AUTOSAR XML (schema 00044)
package /E40_Platform_System_SystemPackage/Components
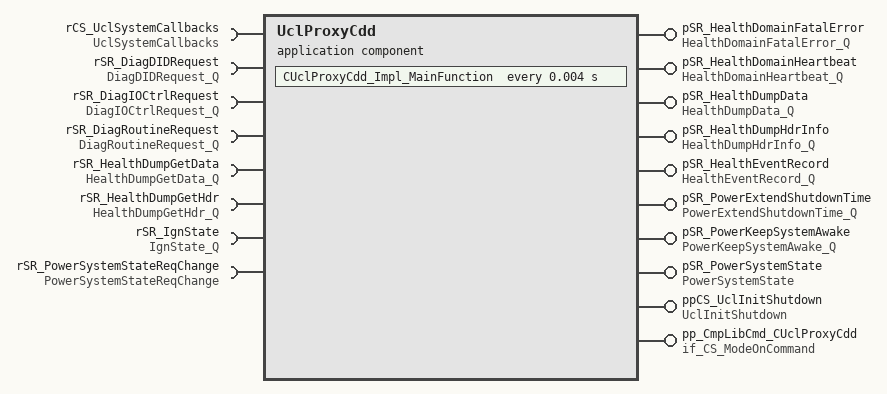
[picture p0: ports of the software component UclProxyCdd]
  application sw component type UclProxyCdd
    10 x provide port:
      pSR_HealthDomainFatalError: queued-sender-com-spec=HealthDomainFatalErrorData, provided-interface=HealthDomainFatalError_Q
      pSR_HealthDomainHeartbeat: queued-sender-com-spec=HealthDomainHeartbeatData, provided-interface=HealthDomainHeartbeat_Q
      pSR_HealthDumpData: queued-sender-com-spec=HealthDumpDataData, provided-interface=HealthDumpData_Q
      pSR_HealthDumpHdrInfo: queued-sender-com-spec=HealthDumpHdrInfoData, provided-interface=HealthDumpHdrInfo_Q
      pSR_HealthEventRecord: queued-sender-com-spec=HealthEventRecordData, provided-interface=HealthEventRecord_Q
      pSR_PowerExtendShutdownTime: queued-sender-com-spec=PowerExtendShutdownTimeData, provided-interface=PowerExtendShutdownTime_Q
      pSR_PowerKeepSystemAwake: queued-sender-com-spec=PowerKeepSystemAwakeData, provided-interface=PowerKeepSystemAwake_Q
      pSR_PowerSystemState: nonqueued-sender-com-spec{data-element=PowerSystemStateData, init-value=constant-reference=UclProxyCddPowerSystemStateDataValue0}, provided-interface=PowerSystemState
      ppCS_UclInitShutdown: provided-com-specs=[{operation=Impl_Initialize, queue-length=1}, {operation=Impl_Shutdown, queue-length=1}], provided-interface=UclInitShutdown
      pp_CmpLibCmd_CUclProxyCdd: server-com-spec{operation=Impl_OnCommand, queue-length=1}, provided-interface=if_CS_ModeOnCommand
    8 x require port:
      rCS_UclSystemCallbacks: required-com-specs=[ErrorNotification, LinkStatusChanged], required-interface=UclSystemCallbacks
      rSR_DiagDIDRequest: queued-receiver-com-spec{data-element=DiagDIDRequestData, queue-length=2}, required-interface=DiagDIDRequest_Q
      rSR_DiagIOCtrlRequest: queued-receiver-com-spec{data-element=DiagIOCtrlRequestData, queue-length=2}, required-interface=DiagIOCtrlRequest_Q
      rSR_DiagRoutineRequest: queued-receiver-com-spec{data-element=DiagRoutineRequestData, queue-length=2}, required-interface=DiagRoutineRequest_Q
      rSR_HealthDumpGetData: queued-receiver-com-spec{data-element=HealthDumpGetDataData, queue-length=1}, required-interface=HealthDumpGetData_Q
      rSR_HealthDumpGetHdr: queued-receiver-com-spec{data-element=HealthDumpGetHdrData, queue-length=1}, required-interface=HealthDumpGetHdr_Q
      rSR_IgnState: queued-receiver-com-spec{data-element=IgnStateData, queue-length=5}, required-interface=IgnState_Q
      rSR_PowerSystemStateReqChange: nonqueued-receiver-com-spec{data-element=PowerSystemStateReqChangeData, init-value=constant-reference=UclProxyCddPowerSystemStateReqChangeDataValue0}, required-interface=PowerSystemStateReqChange
    behavior IB_UclProxyCdd
      operation invoked event OIE_ppCS_UclInitShutdown_CUclProxyCdd_Impl_InitializeTrigByImpl_Initialize: start-on-event=CUclProxyCdd_Impl_Initialize, operation=ppCS_UclInitShutdown.Impl_Initialize
      timing event TECUclProxyCdd_Impl_MainFunction: start-on-event=CUclProxyCdd_Impl_MainFunction, period=0.004
      operation invoked event OIE_pp_CmpLibCmd_CUclProxyCdd_CUclProxyCdd_Impl_OnCommandTrigByImpl_OnCommand: start-on-event=CUclProxyCdd_Impl_OnCommand, operation=pp_CmpLibCmd_CUclProxyCdd.Impl_OnCommand
      operation invoked event OIE_ppCS_UclInitShutdown_CUclProxyCdd_Impl_ShutdownTrigByImpl_Shutdown: start-on-event=CUclProxyCdd_Impl_Shutdown, operation=ppCS_UclInitShutdown.Impl_Shutdown
      data received event DREOnDre_HealthDumpGetDataTrigByHealthDumpGetDataData: start-on-event=OnDre_HealthDumpGetData, data=rSR_HealthDumpGetData.HealthDumpGetDataData
      data received event DREOnDre_HealthDumpGetHdrTrigByHealthDumpGetHdrData: start-on-event=OnDre_HealthDumpGetHdr, data=rSR_HealthDumpGetHdr.HealthDumpGetHdrData
      data received event DREOnDre_PowerSystemStateReqChangeTrigByPowerSystemStateReqChangeData: start-on-event=OnDre_PowerSystemStateReqChange, data=rSR_PowerSystemStateReqChange.PowerSystemStateReqChangeData
      port-api-options:
        enable-take-address=false, indirect-api=false, port=pSR_HealthDomainFatalError
        enable-take-address=false, indirect-api=false, port=pSR_HealthDomainHeartbeat
        enable-take-address=false, indirect-api=false, port=pSR_HealthDumpData
        enable-take-address=false, indirect-api=false, port=pSR_HealthDumpHdrInfo
        enable-take-address=false, indirect-api=false, port=pSR_HealthEventRecord
        enable-take-address=false, indirect-api=false, port=pSR_PowerExtendShutdownTime
        enable-take-address=false, indirect-api=false, port=pSR_PowerKeepSystemAwake
        enable-take-address=false, indirect-api=false, port=pSR_PowerSystemState
        enable-take-address=false, indirect-api=false, port=ppCS_UclInitShutdown
        enable-take-address=false, indirect-api=false, port=pp_CmpLibCmd_CUclProxyCdd
        enable-take-address=false, indirect-api=false, port=rCS_UclSystemCallbacks
        enable-take-address=false, indirect-api=false, port=rSR_DiagDIDRequest
        enable-take-address=false, indirect-api=false, port=rSR_DiagIOCtrlRequest
        enable-take-address=false, indirect-api=false, port=rSR_DiagRoutineRequest
        enable-take-address=false, indirect-api=false, port=rSR_HealthDumpGetData
        enable-take-address=false, indirect-api=false, port=rSR_HealthDumpGetHdr
        enable-take-address=false, indirect-api=false, port=rSR_IgnState
        enable-take-address=false, indirect-api=false, port=rSR_PowerSystemStateReqChange
      7 x runnable, all with can-be-invoked-concurrently=true:
        CUclProxyCdd_Impl_Initialize
        CUclProxyCdd_Impl_MainFunction
          data-receive-point-by-arguments:
            7 x access:
              DRP_rSR_DiagDIDRequest_DiagDIDRequestData: accessed-variable=rSR_DiagDIDRequest.DiagDIDRequestData
              DRP_rSR_DiagIOCtrlRequest_DiagIOCtrlRequestData: accessed-variable=rSR_DiagIOCtrlRequest.DiagIOCtrlRequestData
              DRP_rSR_DiagRoutineRequest_DiagRoutineRequestData: accessed-variable=rSR_DiagRoutineRequest.DiagRoutineRequestData
              DRP_rSR_HealthDumpGetData_HealthDumpGetDataData: accessed-variable=rSR_HealthDumpGetData.HealthDumpGetDataData
              DRP_rSR_HealthDumpGetHdr_HealthDumpGetHdrData: accessed-variable=rSR_HealthDumpGetHdr.HealthDumpGetHdrData
              DRP_rSR_IgnState_IgnStateData: accessed-variable=rSR_IgnState.IgnStateData
              DRA_rSR_PowerSystemStateReqChange_PowerSystemStateReqChangeData: accessed-variable=rSR_PowerSystemStateReqChange.PowerSystemStateReqChangeData
          data-send-points:
            8 x access:
              DSP_pSR_HealthDomainFatalError_HealthDomainFatalErrorData: accessed-variable=pSR_HealthDomainFatalError.HealthDomainFatalErrorData
              DSP_pSR_HealthDomainHeartbeat_HealthDomainHeartbeatData: accessed-variable=pSR_HealthDomainHeartbeat.HealthDomainHeartbeatData
              DSP_pSR_HealthDumpData_HealthDumpDataData: accessed-variable=pSR_HealthDumpData.HealthDumpDataData
              DSP_pSR_HealthDumpHdrInfo_HealthDumpHdrInfoData: accessed-variable=pSR_HealthDumpHdrInfo.HealthDumpHdrInfoData
              DSP_pSR_HealthEventRecord_HealthEventRecordData: accessed-variable=pSR_HealthEventRecord.HealthEventRecordData
              DSP_pSR_PowerExtendShutdownTime_PowerExtendShutdownTimeData: accessed-variable=pSR_PowerExtendShutdownTime.PowerExtendShutdownTimeData
              DSP_pSR_PowerKeepSystemAwake_PowerKeepSystemAwakeData: accessed-variable=pSR_PowerKeepSystemAwake.PowerKeepSystemAwakeData
              DWA_pSR_PowerSystemState_PowerSystemStateData: accessed-variable=pSR_PowerSystemState.PowerSystemStateData
          sync call OA_rCS_UclSystemCallbacks_ErrorNotification: operation=rCS_UclSystemCallbacks.ErrorNotification
          sync call OA_rCS_UclSystemCallbacks_LinkStatusChanged: operation=rCS_UclSystemCallbacks.LinkStatusChanged
        CUclProxyCdd_Impl_OnCommand
        CUclProxyCdd_Impl_Shutdown
        OnDre_HealthDumpGetData
          data-receive-point-by-arguments:
            7 x access:
              DRP_rSR_DiagDIDRequest_DiagDIDRequestData: accessed-variable=rSR_DiagDIDRequest.DiagDIDRequestData
              DRP_rSR_DiagIOCtrlRequest_DiagIOCtrlRequestData: accessed-variable=rSR_DiagIOCtrlRequest.DiagIOCtrlRequestData
              DRP_rSR_DiagRoutineRequest_DiagRoutineRequestData: accessed-variable=rSR_DiagRoutineRequest.DiagRoutineRequestData
              DRP_rSR_HealthDumpGetData_HealthDumpGetDataData: accessed-variable=rSR_HealthDumpGetData.HealthDumpGetDataData
              DRP_rSR_HealthDumpGetHdr_HealthDumpGetHdrData: accessed-variable=rSR_HealthDumpGetHdr.HealthDumpGetHdrData
              DRP_rSR_IgnState_IgnStateData: accessed-variable=rSR_IgnState.IgnStateData
              DRA_rSR_PowerSystemStateReqChange_PowerSystemStateReqChangeData: accessed-variable=rSR_PowerSystemStateReqChange.PowerSystemStateReqChangeData
          data-send-points:
            8 x access:
              DSP_pSR_HealthDomainFatalError_HealthDomainFatalErrorData: accessed-variable=pSR_HealthDomainFatalError.HealthDomainFatalErrorData
              DSP_pSR_HealthDomainHeartbeat_HealthDomainHeartbeatData: accessed-variable=pSR_HealthDomainHeartbeat.HealthDomainHeartbeatData
              DSP_pSR_HealthDumpData_HealthDumpDataData: accessed-variable=pSR_HealthDumpData.HealthDumpDataData
              DSP_pSR_HealthDumpHdrInfo_HealthDumpHdrInfoData: accessed-variable=pSR_HealthDumpHdrInfo.HealthDumpHdrInfoData
              DSP_pSR_HealthEventRecord_HealthEventRecordData: accessed-variable=pSR_HealthEventRecord.HealthEventRecordData
              DSP_pSR_PowerExtendShutdownTime_PowerExtendShutdownTimeData: accessed-variable=pSR_PowerExtendShutdownTime.PowerExtendShutdownTimeData
              DSP_pSR_PowerKeepSystemAwake_PowerKeepSystemAwakeData: accessed-variable=pSR_PowerKeepSystemAwake.PowerKeepSystemAwakeData
              DWA_pSR_PowerSystemState_PowerSystemStateData: accessed-variable=pSR_PowerSystemState.PowerSystemStateData
          sync call OA_rCS_UclSystemCallbacks_ErrorNotification: operation=rCS_UclSystemCallbacks.ErrorNotification
          sync call OA_rCS_UclSystemCallbacks_LinkStatusChanged: operation=rCS_UclSystemCallbacks.LinkStatusChanged
        OnDre_HealthDumpGetHdr
          data-receive-point-by-arguments:
            7 x access:
              DRP_rSR_DiagDIDRequest_DiagDIDRequestData: accessed-variable=rSR_DiagDIDRequest.DiagDIDRequestData
              DRP_rSR_DiagIOCtrlRequest_DiagIOCtrlRequestData: accessed-variable=rSR_DiagIOCtrlRequest.DiagIOCtrlRequestData
              DRP_rSR_DiagRoutineRequest_DiagRoutineRequestData: accessed-variable=rSR_DiagRoutineRequest.DiagRoutineRequestData
              DRP_rSR_HealthDumpGetData_HealthDumpGetDataData: accessed-variable=rSR_HealthDumpGetData.HealthDumpGetDataData
              DRP_rSR_HealthDumpGetHdr_HealthDumpGetHdrData: accessed-variable=rSR_HealthDumpGetHdr.HealthDumpGetHdrData
              DRP_rSR_IgnState_IgnStateData: accessed-variable=rSR_IgnState.IgnStateData
              DRA_rSR_PowerSystemStateReqChange_PowerSystemStateReqChangeData: accessed-variable=rSR_PowerSystemStateReqChange.PowerSystemStateReqChangeData
          data-send-points:
            8 x access:
              DSP_pSR_HealthDomainFatalError_HealthDomainFatalErrorData: accessed-variable=pSR_HealthDomainFatalError.HealthDomainFatalErrorData
              DSP_pSR_HealthDomainHeartbeat_HealthDomainHeartbeatData: accessed-variable=pSR_HealthDomainHeartbeat.HealthDomainHeartbeatData
              DSP_pSR_HealthDumpData_HealthDumpDataData: accessed-variable=pSR_HealthDumpData.HealthDumpDataData
              DSP_pSR_HealthDumpHdrInfo_HealthDumpHdrInfoData: accessed-variable=pSR_HealthDumpHdrInfo.HealthDumpHdrInfoData
              DSP_pSR_HealthEventRecord_HealthEventRecordData: accessed-variable=pSR_HealthEventRecord.HealthEventRecordData
              DSP_pSR_PowerExtendShutdownTime_PowerExtendShutdownTimeData: accessed-variable=pSR_PowerExtendShutdownTime.PowerExtendShutdownTimeData
              DSP_pSR_PowerKeepSystemAwake_PowerKeepSystemAwakeData: accessed-variable=pSR_PowerKeepSystemAwake.PowerKeepSystemAwakeData
              DWA_pSR_PowerSystemState_PowerSystemStateData: accessed-variable=pSR_PowerSystemState.PowerSystemStateData
          sync call OA_rCS_UclSystemCallbacks_ErrorNotification: operation=rCS_UclSystemCallbacks.ErrorNotification
          sync call OA_rCS_UclSystemCallbacks_LinkStatusChanged: operation=rCS_UclSystemCallbacks.LinkStatusChanged
        OnDre_PowerSystemStateReqChange
          data-receive-point-by-arguments:
            7 x access:
              DRP_rSR_DiagDIDRequest_DiagDIDRequestData: accessed-variable=rSR_DiagDIDRequest.DiagDIDRequestData
              DRP_rSR_DiagIOCtrlRequest_DiagIOCtrlRequestData: accessed-variable=rSR_DiagIOCtrlRequest.DiagIOCtrlRequestData
              DRP_rSR_DiagRoutineRequest_DiagRoutineRequestData: accessed-variable=rSR_DiagRoutineRequest.DiagRoutineRequestData
              DRP_rSR_HealthDumpGetData_HealthDumpGetDataData: accessed-variable=rSR_HealthDumpGetData.HealthDumpGetDataData
              DRP_rSR_HealthDumpGetHdr_HealthDumpGetHdrData: accessed-variable=rSR_HealthDumpGetHdr.HealthDumpGetHdrData
              DRP_rSR_IgnState_IgnStateData: accessed-variable=rSR_IgnState.IgnStateData
              DRA_rSR_PowerSystemStateReqChange_PowerSystemStateReqChangeData: accessed-variable=rSR_PowerSystemStateReqChange.PowerSystemStateReqChangeData
          data-send-points:
            8 x access:
              DSP_pSR_HealthDomainFatalError_HealthDomainFatalErrorData: accessed-variable=pSR_HealthDomainFatalError.HealthDomainFatalErrorData
              DSP_pSR_HealthDomainHeartbeat_HealthDomainHeartbeatData: accessed-variable=pSR_HealthDomainHeartbeat.HealthDomainHeartbeatData
              DSP_pSR_HealthDumpData_HealthDumpDataData: accessed-variable=pSR_HealthDumpData.HealthDumpDataData
              DSP_pSR_HealthDumpHdrInfo_HealthDumpHdrInfoData: accessed-variable=pSR_HealthDumpHdrInfo.HealthDumpHdrInfoData
              DSP_pSR_HealthEventRecord_HealthEventRecordData: accessed-variable=pSR_HealthEventRecord.HealthEventRecordData
              DSP_pSR_PowerExtendShutdownTime_PowerExtendShutdownTimeData: accessed-variable=pSR_PowerExtendShutdownTime.PowerExtendShutdownTimeData
              DSP_pSR_PowerKeepSystemAwake_PowerKeepSystemAwakeData: accessed-variable=pSR_PowerKeepSystemAwake.PowerKeepSystemAwakeData
              DWA_pSR_PowerSystemState_PowerSystemStateData: accessed-variable=pSR_PowerSystemState.PowerSystemStateData
          sync call OA_rCS_UclSystemCallbacks_ErrorNotification: operation=rCS_UclSystemCallbacks.ErrorNotification
          sync call OA_rCS_UclSystemCallbacks_LinkStatusChanged: operation=rCS_UclSystemCallbacks.LinkStatusChanged
  swc implementation IMPL_UclProxyCdd: behavior=IB_UclProxyCdd
